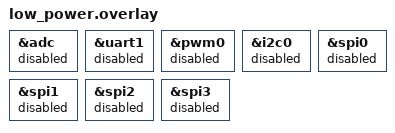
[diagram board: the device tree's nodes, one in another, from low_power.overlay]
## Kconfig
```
#
# Copyright (c) 2020 Nordic Semiconductor ASA
#
# SPDX-License-Identifier: LicenseRef-Nordic-5-Clause
#

menu "Zephyr Kernel"
source "Kconfig.zephyr"
endmenu

module = OT_COMMAND_LINE_INTERFACE
module-str = ot_cli
source "${ZEPHYR_BASE}/subsys/logging/Kconfig.template.log_config"

config CLI_SAMPLE_LOW_POWER
    bool "Enable low power mode for the CLI sample"
```

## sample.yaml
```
sample:
  name: OpenThread CLI sample
  description: Test OpenThread Command Line Interface.
common:
  build_only: true
  integration_platforms:
    - connectkit_nrf52840
    - dongle_nrf52840
tests:
  sample.openthread.cli: {}
  sample.openthread.cli.low_power:
    extra_args: OVERLAY_CONFIG=overlay-low_power.conf
                DTC_OVERLAY_FILE=low_power.overlay
  sample.openthread.cli.multiprotocol:
    extra_args: OVERLAY_CONFIG=overlay-multiprotocol.conf
```

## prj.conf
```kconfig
#
# Copyright (c) 2020 Nordic Semiconductor
#
# SPDX-License-Identifier: LicenseRef-Nordic-5-Clause
#

# Network shell
CONFIG_SHELL=y
CONFIG_OPENTHREAD_SHELL=y
CONFIG_SHELL_ARGC_MAX=26
CONFIG_SHELL_CMD_BUFF_SIZE=416

# Enable OpenThread features set
CONFIG_OPENTHREAD_NORDIC_LIBRARY_MASTER=y

CONFIG_NET_L2_OPENTHREAD=y

# Generic networking options
CONFIG_NETWORKING=y

CONFIG_MBEDTLS_SHA1_C=n
CONFIG_FPU=y

CONFIG_GPIO_SHELL=y

# Enable USB transport support
CONFIG_SHELL_BACKEND_SERIAL_INIT_PRIORITY=51

CONFIG_UART_LINE_CTRL=y
CONFIG_SHELL_BACKEND_SERIAL_CHECK_DTR=y
CONFIG_USB_CDC_ACM_LOG_LEVEL_OFF=y

CONFIG_USB_DEVICE_STACK=y
CONFIG_USB_DEVICE_REMOTE_WAKEUP=n
CONFIG_USB_DEVICE_MANUFACTURER="Nordic Semiconductor ASA"
CONFIG_USB_DEVICE_PRODUCT="Thread CLI"
CONFIG_USB_DEVICE_VID=0x1915
CONFIG_USB_DEVICE_PID=0x0000
```

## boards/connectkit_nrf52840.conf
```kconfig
# Enable USB transport support
CONFIG_SHELL_BACKEND_SERIAL_INIT_PRIORITY=51

CONFIG_UART_LINE_CTRL=y
CONFIG_SHELL_BACKEND_SERIAL_CHECK_DTR=y
CONFIG_USB_CDC_ACM_LOG_LEVEL_OFF=y

CONFIG_USB_DEVICE_STACK=y
CONFIG_USB_DEVICE_REMOTE_WAKEUP=n
CONFIG_USB_DEVICE_MANUFACTURER="Nordic Semiconductor ASA"
CONFIG_USB_DEVICE_PRODUCT="Thread CLI"
CONFIG_USB_DEVICE_VID=0x1915
CONFIG_USB_DEVICE_PID=0x0000
```

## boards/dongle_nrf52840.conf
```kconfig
#
# Copyright (c) 2016-2023 Makerdiary
#
# SPDX-License-Identifier: Apache-2.0
#

# Enable USB transport support
CONFIG_SHELL_BACKEND_SERIAL_INIT_PRIORITY=51

CONFIG_UART_LINE_CTRL=y
CONFIG_SHELL_BACKEND_SERIAL_CHECK_DTR=y
CONFIG_USB_CDC_ACM_LOG_LEVEL_OFF=y

CONFIG_USB_DEVICE_STACK=y
CONFIG_USB_DEVICE_REMOTE_WAKEUP=n
CONFIG_USB_DEVICE_MANUFACTURER="Nordic Semiconductor ASA"
CONFIG_USB_DEVICE_PRODUCT="Thread CLI"
CONFIG_USB_DEVICE_VID=0x1915
CONFIG_USB_DEVICE_PID=0x0000
CONFIG_USB_DEVICE_INITIALIZE_AT_BOOT=n
```

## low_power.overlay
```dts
/*
 * Copyright (c) 2023 Nordic Semiconductor ASA
 *
 * SPDX-License-Identifier: LicenseRef-Nordic-5-Clause
 */

&adc {
    status = "disabled";
};
&uart1 {
    status = "disabled";
};
&pwm0 {
    status = "disabled";
};
&i2c0 {
    status = "disabled";
};
&spi0 {
    status = "disabled";
};
&spi1 {
    status = "disabled";
};
&spi2 {
    status = "disabled";
};
&spi3 {
    status = "disabled";
};
```

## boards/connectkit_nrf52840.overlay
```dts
/* Copyright (c) 2020 Nordic Semiconductor ASA
 * Copyright (c) 2016-2023 Makerdiary
 *
 * SPDX-License-Identifier: LicenseRef-Nordic-5-Clause
 */

&uart0 {
    status = "okay";
    hw-flow-control;
};

&zephyr_udc0 {
    cdc_acm_uart0: cdc_acm_uart0 {
        compatible = "zephyr,cdc-acm-uart";
    };
};

/ {
    /*
    * In some default configurations within the nRF Connect SDK,
    * e.g. on nRF52840, the chosen zephyr,entropy node is &cryptocell.
    * This devicetree overlay ensures that default is overridden wherever it
    * is set, as this application uses the RNG node for entropy exclusively.
    */
    chosen {
        zephyr,entropy = &rng;
        zephyr,shell-uart = &cdc_acm_uart0;
    };
};
```

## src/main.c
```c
/*
 * Copyright (c) 2020 Nordic Semiconductor ASA
 * Copyright (c) 2016-2023 Makerdiary
 *
 * SPDX-License-Identifier: LicenseRef-Nordic-5-Clause
 */

#include <zephyr/kernel.h>
#include <zephyr/logging/log.h>

#if defined(CONFIG_BT)
#include "ble.h"
#endif

#if defined(CONFIG_CLI_SAMPLE_LOW_POWER)
#include "low_power.h"
#endif

#include <zephyr/drivers/uart.h>
#include <zephyr/usb/usb_device.h>

LOG_MODULE_REGISTER(cli_sample, CONFIG_OT_COMMAND_LINE_INTERFACE_LOG_LEVEL);

#define WELLCOME_TEXT \
    "\n\r"\
    "\n\r"\
    "OpenThread Command Line Interface is now running.\n\r" \
    "Use the 'ot' keyword to invoke OpenThread commands e.g. " \
    "'ot thread start.'\n\r" \
    "For the full commands list refer to the OpenThread CLI " \
    "documentation at:\n\r" \
    "https://github.com/openthread/openthread/blob/master/src/cli/README.md\n\r"

int main(void)
{
#if DT_NODE_HAS_COMPAT(DT_CHOSEN(zephyr_shell_uart), zephyr_cdc_acm_uart)
    int ret;
    const struct device *dev;
    uint32_t dtr = 0U;

    ret = usb_enable(NULL);
    if (ret != 0) {
        LOG_ERR("Failed to enable USB");
        return 0;
    }

    dev = DEVICE_DT_GET(DT_CHOSEN(zephyr_shell_uart));
    if (dev == NULL) {
        LOG_ERR("Failed to find specific UART device");
        return 0;
    }

    LOG_INF("Waiting for host to be ready to communicate");

    /* Data Terminal Ready - check if host is ready to communicate */
    while (!dtr) {
        ret = uart_line_ctrl_get(dev, UART_LINE_CTRL_DTR, &dtr);
        if (ret) {
            LOG_ERR("Failed to get Data Terminal Ready line state: %d",
                ret);
            continue;
        }
        k_msleep(100);
    }

    /* Data Carrier Detect Modem - mark connection as established */
    (void)uart_line_ctrl_set(dev, UART_LINE_CTRL_DCD, 1);
    /* Data Set Ready - the NCP SoC is ready to communicate */
    (void)uart_line_ctrl_set(dev, UART_LINE_CTRL_DSR, 1);
#endif

    LOG_INF(WELLCOME_TEXT);

#if defined(CONFIG_BT)
    ble_enable();
#endif

#if defined(CONFIG_CLI_SAMPLE_LOW_POWER)
    low_power_enable();
#endif

    return 0;
}
```

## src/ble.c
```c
/*
 * Copyright (c) 2020 Nordic Semiconductor ASA
 *
 * SPDX-License-Identifier: LicenseRef-Nordic-5-Clause
 */

#include <zephyr/kernel.h>
#include <zephyr/bluetooth/gatt.h>

#include "ble.h"

#define DEVICE_NAME CONFIG_BT_DEVICE_NAME
#define DEVICE_NAME_LEN (sizeof(DEVICE_NAME) - 1)

#define ADV_INT_MIN 0x01e0 /* 300 ms */
#define ADV_INT_MAX 0x0260 /* 380 ms */

static const struct bt_data ad[] = {
    BT_DATA_BYTES(BT_DATA_FLAGS, (BT_LE_AD_GENERAL | BT_LE_AD_NO_BREDR)),
    BT_DATA(BT_DATA_NAME_COMPLETE, DEVICE_NAME, DEVICE_NAME_LEN),
};

static struct bt_conn_cb conn_callbacks;

void ble_enable(void)
{
    struct bt_le_adv_param *adv_param = BT_LE_ADV_PARAM(
        BT_LE_ADV_OPT_CONNECTABLE | BT_LE_ADV_OPT_ONE_TIME, ADV_INT_MIN, ADV_INT_MAX, NULL);

    bt_enable(NULL);
    bt_conn_cb_register(&conn_callbacks);
    bt_le_adv_start(adv_param, ad, ARRAY_SIZE(ad), NULL, 0);
}
```

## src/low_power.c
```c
/*
 * Copyright (c) 2023 Nordic Semiconductor ASA
 *
 * SPDX-License-Identifier: LicenseRef-Nordic-5-Clause
 */

#include <openthread/thread.h>
#include <zephyr/net/openthread.h>
#include <zephyr/device.h>
#include <zephyr/pm/device.h>
#include <ram_pwrdn.h>

#include "low_power.h"

static void on_thread_state_changed(otChangedFlags flags, struct openthread_context *ot_context,
                    void *user_data)
{
    if (flags & OT_CHANGED_THREAD_ROLE) {
        if (otThreadGetDeviceRole(ot_context->instance) == OT_DEVICE_ROLE_CHILD) {
            const struct device *cons = DEVICE_DT_GET(DT_CHOSEN(zephyr_console));

            if (!device_is_ready(cons)) {
                return;
            }

            pm_device_action_run(cons, PM_DEVICE_ACTION_SUSPEND);
            power_down_unused_ram();
        }
    }
}

static struct openthread_state_changed_cb ot_state_chaged_cb = {
    .state_changed_cb = on_thread_state_changed
};

void low_power_enable(void)
{
    openthread_state_changed_cb_register(openthread_get_default_context(), &ot_state_chaged_cb);
}
```
